# PIC32MX775F512L register map
Vendor: Microchip
Registers are 32-bit, read-write, reset 0x0 unless marked. A register's access mark holds for its fields unless they carry their own. Addresses are absolute, and some are shared; only a register's first bit layout is shown; [hi:lo] are bit positions; {n}, {i} and the like mark numbered series.

## PORTB
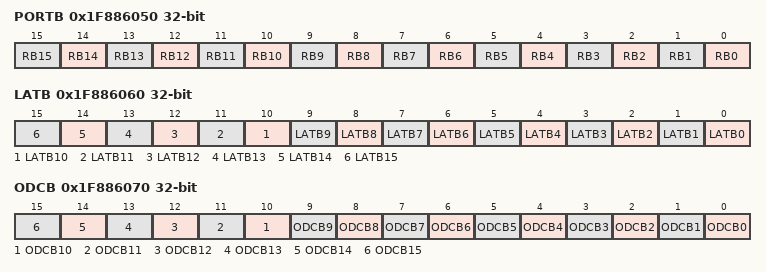
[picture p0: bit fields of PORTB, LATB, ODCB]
0x1F886050 PORTB reset not defined — (power-on value ----------------xxxxxxxxxxxxxxxx)
  [n] RB{n} (n=0..15)
0x1F886060 LATB reset not defined — (power-on value ----------------xxxxxxxxxxxxxxxx)
  [n] LATB{n} (n=0..15)
0x1F886070 ODCB
  [n] ODCB{n} (n=0..15)

## PORTC
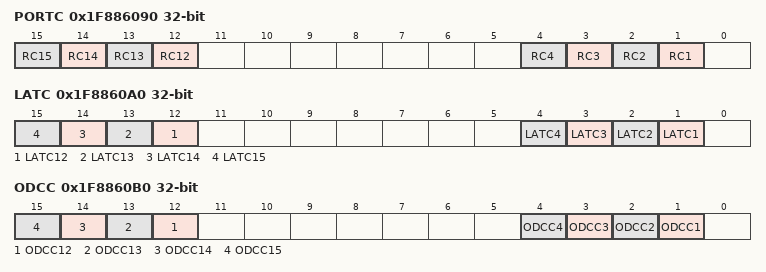
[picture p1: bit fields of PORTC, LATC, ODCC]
0x1F886090 PORTC reset not defined — (power-on value ----------------xxxx-------xxxx-)
  [n] RC{n} (n=12..15), [n] RC{n} (n=1..4)
0x1F8860A0 LATC reset not defined — (power-on value ----------------xxxx-------xxxx-)
  [n] LATC{n} (n=12..15), [n] LATC{n} (n=1..4)
0x1F8860B0 ODCC
  [n] ODCC{n} (n=12..15), [n] ODCC{n} (n=1..4)

## PORTD
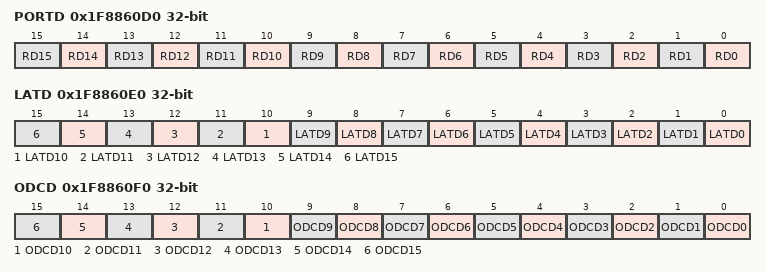
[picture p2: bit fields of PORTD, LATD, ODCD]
0x1F8860D0 PORTD reset not defined — (power-on value ----------------xxxxxxxxxxxxxxxx)
  [n] RD{n} (n=0..15)
0x1F8860E0 LATD reset not defined — (power-on value ----------------xxxxxxxxxxxxxxxx)
  [n] LATD{n} (n=0..15)
0x1F8860F0 ODCD
  [n] ODCD{n} (n=0..15)

## PORTE
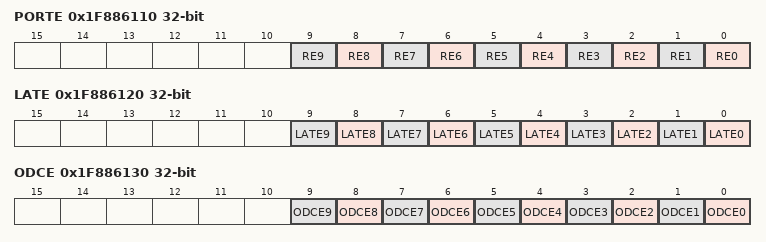
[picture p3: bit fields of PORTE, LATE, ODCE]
0x1F886110 PORTE reset not defined — (power-on value ----------------------xxxxxxxxxx)
  [n] RE{n} (n=0..9)
0x1F886120 LATE reset not defined — (power-on value ----------------------xxxxxxxxxx)
  [n] LATE{n} (n=0..9)
0x1F886130 ODCE
  [n] ODCE{n} (n=0..9)

## PORTF
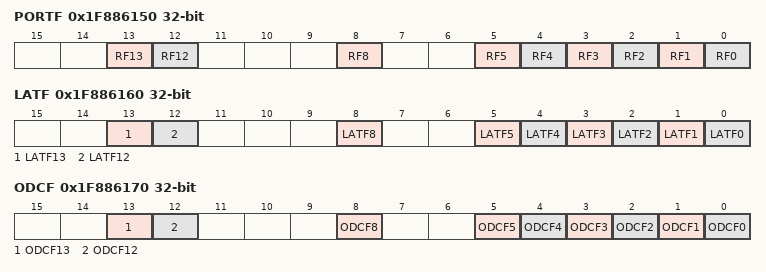
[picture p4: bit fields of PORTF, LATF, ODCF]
0x1F886150 PORTF reset not defined — (power-on value ------------------xx---x--xxxxxx)
  [13] RF13, [12] RF12, [8] RF8, [n] RF{n} (n=0..5)
0x1F886160 LATF reset not defined — (power-on value ------------------xx---x--xxxxxx)
  [13] LATF13, [12] LATF12, [8] LATF8, [n] LATF{n} (n=0..5)
0x1F886170 ODCF
  [13] ODCF13, [12] ODCF12, [8] ODCF8, [n] ODCF{n} (n=0..5)

## TDAA_PortG
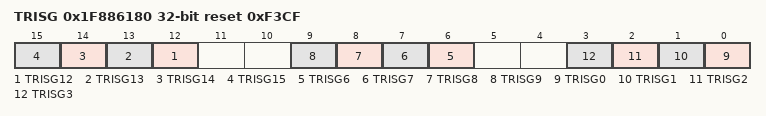
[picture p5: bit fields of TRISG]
0x1F886180 TRISG reset 0xF3CF
  [n] TRISG{n} (n=12..15), [n] TRISG{n} (n=6..9), [n] TRISG{n} (n=0..3)

## PORTG
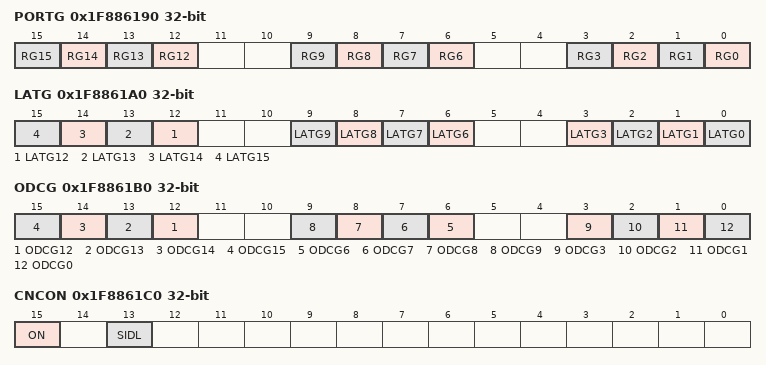
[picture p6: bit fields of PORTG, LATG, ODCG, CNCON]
0x1F886190 PORTG reset not defined — (power-on value ----------------xxxx--xxxx--xxxx)
  [n] RG{n} (n=12..15), [n] RG{n} (n=6..9), [n] RG{n} (n=0..3)
0x1F8861A0 LATG reset not defined — (power-on value ----------------xxxx--xxxx--xxxx)
  [n] LATG{n} (n=12..15), [n] LATG{n} (n=6..9), [3] LATG3 ro, [2] LATG2 ro, [1] LATG1, [0] LATG0
0x1F8861B0 ODCG
  [n] ODCG{n} (n=12..15), [n] ODCG{n} (n=6..9), [3] ODCG3 ro, [2] ODCG2 ro, [1] ODCG1, [0] ODCG0
0x1F8861C0 CNCON
  [15] ON, [13] SIDL
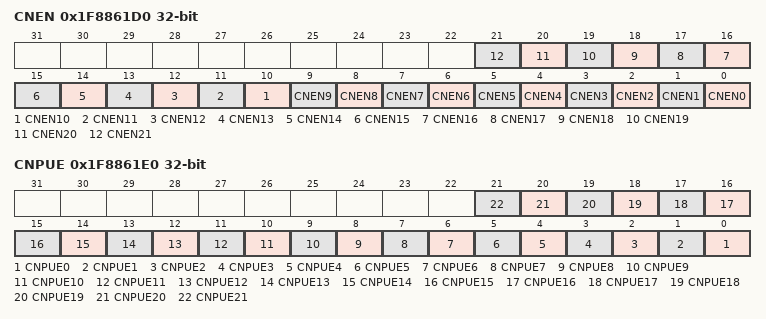
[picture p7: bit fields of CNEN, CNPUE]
0x1F8861D0 CNEN
  [n] CNEN{n} (n=0..21)
0x1F8861E0 CNPUE
  [n] CNPUE{n} (n=0..21)

## CAN1
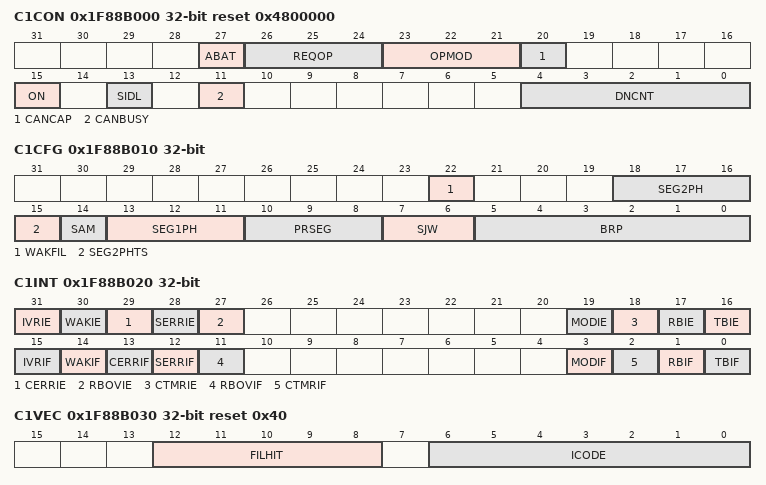
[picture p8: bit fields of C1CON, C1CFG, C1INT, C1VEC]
0x1F88B000 C1CON reset 0x4800000
  [27] ABAT — (can only be set)
  [26:24] REQOP
  [23:21] OPMOD ro
  [20] CANCAP
  [15] ON
  [13] SIDL
  [11] CANBUSY ro
  [4:0] DNCNT
0x1F88B010 C1CFG
  [22] WAKFIL, [18:16] SEG2PH, [15] SEG2PHTS, [14] SAM, [13:11] SEG1PH, [10:8] PRSEG, [7:6] SJW, [5:0] BRP
0x1F88B020 C1INT
  [31] IVRIE, [30] WAKIE, [29] CERRIE, [28] SERRIE, [27] RBOVIE, [19] MODIE, [18] CTMRIE, [17] RBIE, [16] TBIE, [15] IVRIF, [14] WAKIF, [13] CERRIF, [12] SERRIF, [11] RBOVIF, [3] MODIF, [2] CTMRIF, [1] RBIF, [0] TBIF
0x1F88B030 C1VEC ro reset 0x40
  [12:8] FILHIT, [6:0] ICODE
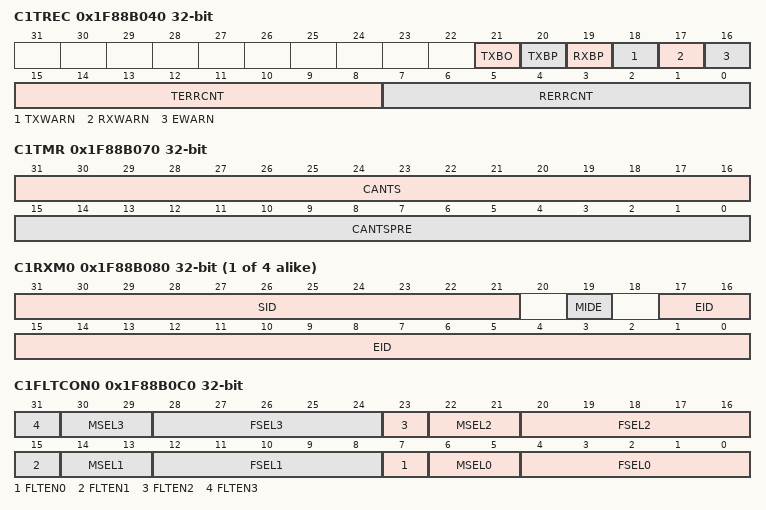
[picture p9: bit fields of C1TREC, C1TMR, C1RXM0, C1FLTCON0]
0x1F88B040 C1TREC ro
  [21] TXBO, [20] TXBP, [19] RXBP, [18] TXWARN, [17] RXWARN, [16] EWARN, [15:8] TERRCNT, [7:0] RERRCNT
0x1F88B050 C1FSTAT ro
  [31:0] FIFOIP
0x1F88B060 C1RXOVF ro
  [31:0] RXOVF
0x1F88B070 C1TMR
  [31:16] CANTS, [15:0] CANTSPRE
{0x1F88B080+0x10*i} C1RXM{i} (i=0..3)
  [31:21] SID, [19] MIDE, [17:0] EID
0x1F88B0C0 C1FLTCON0
  [8n+7] FLTEN{n} (n=0..3), [8n+6:8n+5] MSEL{n} (n=0..3), [8n+4:8n] FSEL{n} (n=0..3)
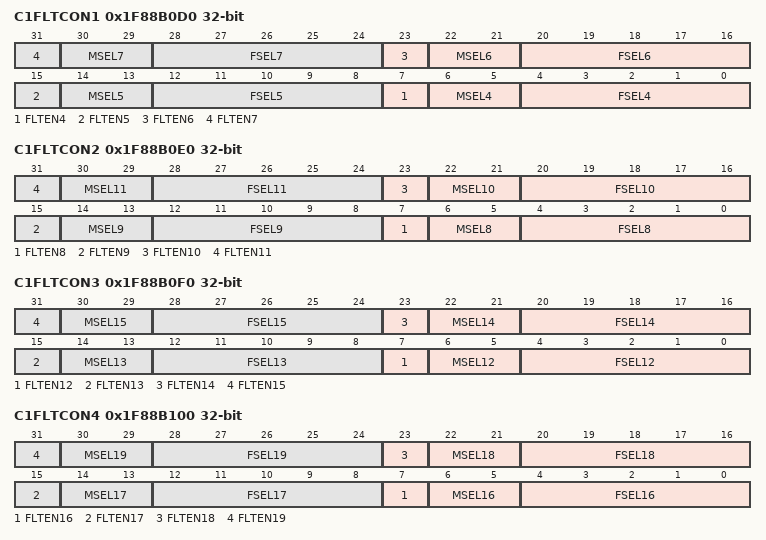
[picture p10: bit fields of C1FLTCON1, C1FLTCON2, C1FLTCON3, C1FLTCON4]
0x1F88B0D0 C1FLTCON1
  [8n-25] FLTEN{n} (n=4..7), [8n-26:8n-27] MSEL{n} (n=4..7), [8n-28:8n-32] FSEL{n} (n=4..7)
0x1F88B0E0 C1FLTCON2
  [8n-57] FLTEN{n} (n=8..11), [8n-58:8n-59] MSEL{n} (n=8..11), [8n-60:8n-64] FSEL{n} (n=8..11)
0x1F88B0F0 C1FLTCON3
  [8n-89] FLTEN{n} (n=12..15), [8n-90:8n-91] MSEL{n} (n=12..15), [8n-92:8n-96] FSEL{n} (n=12..15)
0x1F88B100 C1FLTCON4
  [8n-121] FLTEN{n} (n=16..19), [8n-122:8n-123] MSEL{n} (n=16..19), [8n-124:8n-128] FSEL{n} (n=16..19)
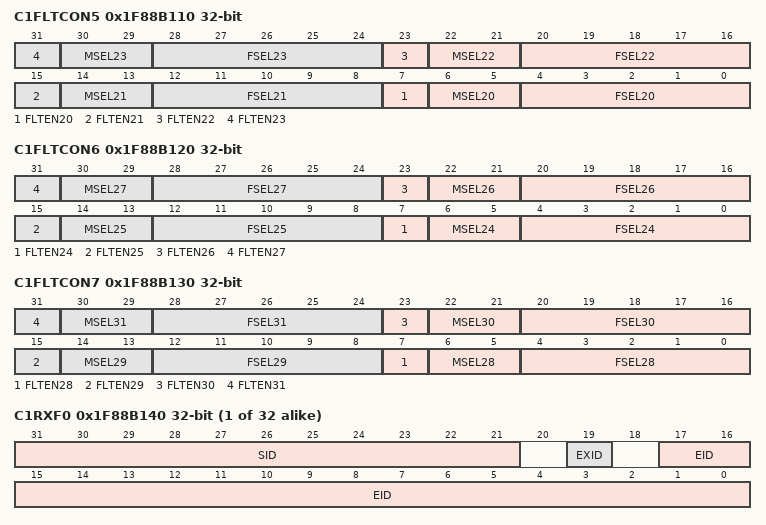
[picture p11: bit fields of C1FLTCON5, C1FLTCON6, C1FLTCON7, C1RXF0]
0x1F88B110 C1FLTCON5
  [8n-153] FLTEN{n} (n=20..23), [8n-154:8n-155] MSEL{n} (n=20..23), [8n-156:8n-160] FSEL{n} (n=20..23)
0x1F88B120 C1FLTCON6
  [8n-185] FLTEN{n} (n=24..27), [8n-186:8n-187] MSEL{n} (n=24..27), [8n-188:8n-192] FSEL{n} (n=24..27)
0x1F88B130 C1FLTCON7
  [8n-217] FLTEN{n} (n=28..31), [8n-218:8n-219] MSEL{n} (n=28..31), [8n-220:8n-224] FSEL{n} (n=28..31)
{0x1F88B140+0x10*i} C1RXF{i} reset not defined (i=0..31) — (power-on value xxxxxxxxxxx0x0xxxxxxxxxxxxxxxxxx)
  [31:21] SID, [19] EXID, [17:0] EID
0x1F88B340 C1FIFOBA
  [31:2] FIFOBA
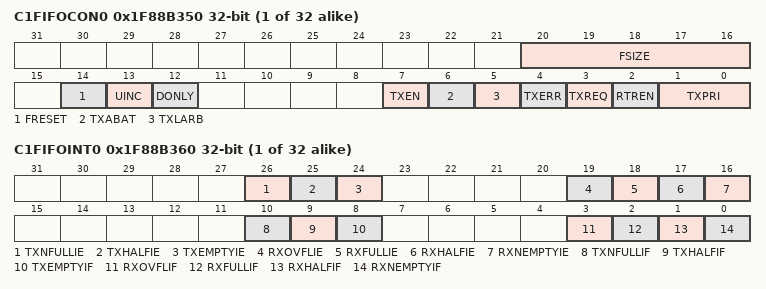
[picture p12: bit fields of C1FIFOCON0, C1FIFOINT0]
{0x1F88B350+0x40*i} C1FIFOCON{i} (i=0..31)
  [20:16] FSIZE, [14] FRESET, [13] UINC, [12] DONLY, [7] TXEN, [6] TXABAT, [5] TXLARB, [4] TXERR, [3] TXREQ, [2] RTREN, [1:0] TXPRI
{0x1F88B360+0x40*i} C1FIFOINT{i} (i=0..31)
  [26] TXNFULLIE, [25] TXHALFIE, [24] TXEMPTYIE, [19] RXOVFLIE, [18] RXFULLIE, [17] RXHALFIE, [16] RXNEMPTYIE, [10] TXNFULLIF ro, [9] TXHALFIF ro, [8] TXEMPTYIF ro, [3] RXOVFLIF, [2] RXFULLIF ro, [1] RXHALFIF ro, [0] RXNEMPTYIF ro
{0x1F88B370+0x40*i} C1FIFOUA{i} ro reset not defined (i=0..31) — (power-on value xxxxxxxxxxxxxxxxxxxxxxxxxxxxxx00)
  [31:2] FIFOUA
{0x1F88B380+0x40*i} C1FIFOCI{i} ro (i=0..31)
  [4:0] CFIFOCI

## CAN2
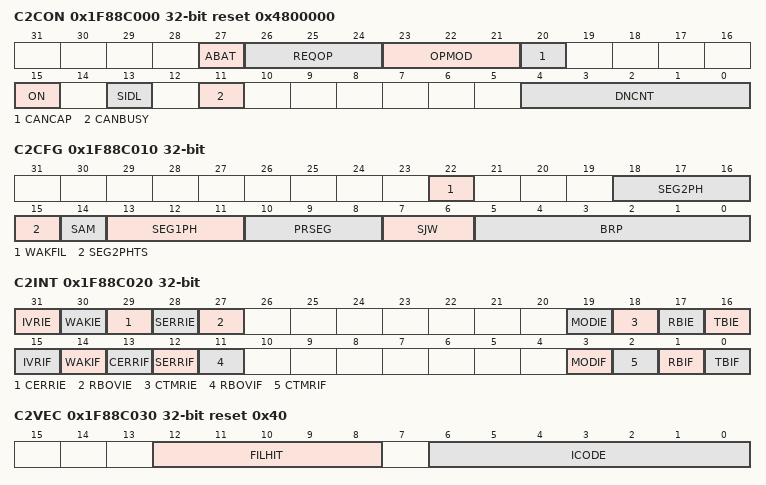
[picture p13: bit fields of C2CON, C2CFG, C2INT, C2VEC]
0x1F88C000 C2CON reset 0x4800000
  [27] ABAT — (can only be set)
  [26:24] REQOP
  [23:21] OPMOD ro
  [20] CANCAP
  [15] ON
  [13] SIDL
  [11] CANBUSY ro
  [4:0] DNCNT
0x1F88C010 C2CFG
  [22] WAKFIL, [18:16] SEG2PH, [15] SEG2PHTS, [14] SAM, [13:11] SEG1PH, [10:8] PRSEG, [7:6] SJW, [5:0] BRP
0x1F88C020 C2INT
  [31] IVRIE, [30] WAKIE, [29] CERRIE, [28] SERRIE, [27] RBOVIE, [19] MODIE, [18] CTMRIE, [17] RBIE, [16] TBIE, [15] IVRIF, [14] WAKIF, [13] CERRIF, [12] SERRIF, [11] RBOVIF, [3] MODIF, [2] CTMRIF, [1] RBIF, [0] TBIF
0x1F88C030 C2VEC ro reset 0x40
  [12:8] FILHIT, [6:0] ICODE
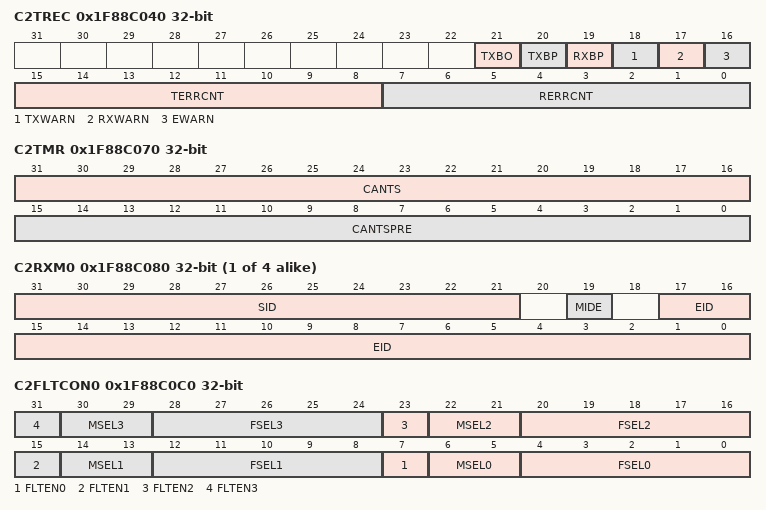
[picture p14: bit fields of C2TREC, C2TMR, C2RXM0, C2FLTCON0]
0x1F88C040 C2TREC ro
  [21] TXBO, [20] TXBP, [19] RXBP, [18] TXWARN, [17] RXWARN, [16] EWARN, [15:8] TERRCNT, [7:0] RERRCNT
0x1F88C050 C2FSTAT ro
  [31:0] FIFOIP
0x1F88C060 C2RXOVF ro
  [31:0] RXOVF
0x1F88C070 C2TMR
  [31:16] CANTS, [15:0] CANTSPRE
{0x1F88C080+0x10*i} C2RXM{i} (i=0..3)
  [31:21] SID, [19] MIDE, [17:0] EID
0x1F88C0C0 C2FLTCON0
  [8n+7] FLTEN{n} (n=0..3), [8n+6:8n+5] MSEL{n} (n=0..3), [8n+4:8n] FSEL{n} (n=0..3)
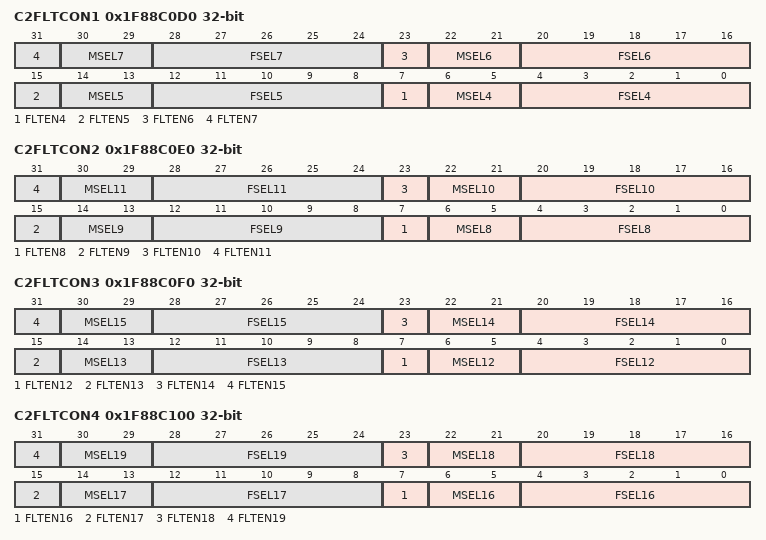
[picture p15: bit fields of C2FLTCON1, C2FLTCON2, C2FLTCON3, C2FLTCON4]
0x1F88C0D0 C2FLTCON1
  [8n-25] FLTEN{n} (n=4..7), [8n-26:8n-27] MSEL{n} (n=4..7), [8n-28:8n-32] FSEL{n} (n=4..7)
0x1F88C0E0 C2FLTCON2
  [8n-57] FLTEN{n} (n=8..11), [8n-58:8n-59] MSEL{n} (n=8..11), [8n-60:8n-64] FSEL{n} (n=8..11)
0x1F88C0F0 C2FLTCON3
  [8n-89] FLTEN{n} (n=12..15), [8n-90:8n-91] MSEL{n} (n=12..15), [8n-92:8n-96] FSEL{n} (n=12..15)
0x1F88C100 C2FLTCON4
  [8n-121] FLTEN{n} (n=16..19), [8n-122:8n-123] MSEL{n} (n=16..19), [8n-124:8n-128] FSEL{n} (n=16..19)
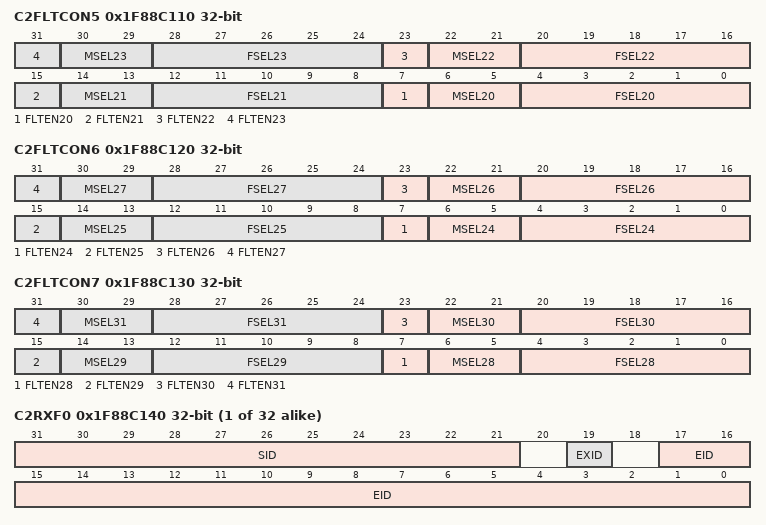
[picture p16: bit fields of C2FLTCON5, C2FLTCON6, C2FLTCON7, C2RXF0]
0x1F88C110 C2FLTCON5
  [8n-153] FLTEN{n} (n=20..23), [8n-154:8n-155] MSEL{n} (n=20..23), [8n-156:8n-160] FSEL{n} (n=20..23)
0x1F88C120 C2FLTCON6
  [8n-185] FLTEN{n} (n=24..27), [8n-186:8n-187] MSEL{n} (n=24..27), [8n-188:8n-192] FSEL{n} (n=24..27)
0x1F88C130 C2FLTCON7
  [8n-217] FLTEN{n} (n=28..31), [8n-218:8n-219] MSEL{n} (n=28..31), [8n-220:8n-224] FSEL{n} (n=28..31)
{0x1F88C140+0x10*i} C2RXF{i} reset not defined (i=0..31) — (power-on value xxxxxxxxxxx0x0xxxxxxxxxxxxxxxxxx)
  [31:21] SID, [19] EXID, [17:0] EID
0x1F88C340 C2FIFOBA
  [31:2] FIFOBA
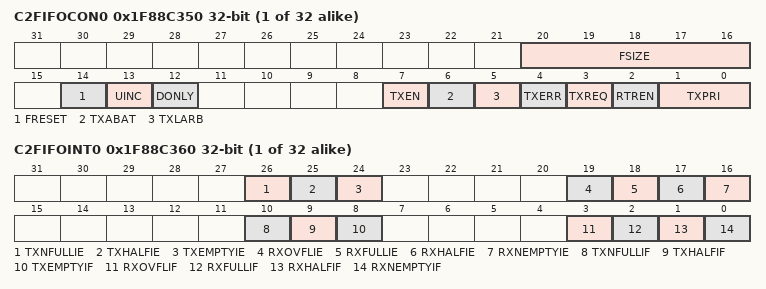
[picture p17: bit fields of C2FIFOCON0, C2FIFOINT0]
{0x1F88C350+0x40*i} C2FIFOCON{i} (i=0..31)
  [20:16] FSIZE, [14] FRESET, [13] UINC, [12] DONLY, [7] TXEN, [6] TXABAT, [5] TXLARB, [4] TXERR, [3] TXREQ, [2] RTREN, [1:0] TXPRI
{0x1F88C360+0x40*i} C2FIFOINT{i} (i=0..31)
  [26] TXNFULLIE, [25] TXHALFIE, [24] TXEMPTYIE, [19] RXOVFLIE, [18] RXFULLIE, [17] RXHALFIE, [16] RXNEMPTYIE, [10] TXNFULLIF ro, [9] TXHALFIF ro, [8] TXEMPTYIF ro, [3] RXOVFLIF, [2] RXFULLIF ro, [1] RXHALFIF ro, [0] RXNEMPTYIF ro
{0x1F88C370+0x40*i} C2FIFOUA{i} ro reset not defined (i=0..31) — (power-on value xxxxxxxxxxxxxxxxxxxxxxxxxxxxxx00)
  [31:2] FIFOUA
{0x1F88C380+0x40*i} C2FIFOCI{i} ro (i=0..31)
  [4:0] CFIFOCI
